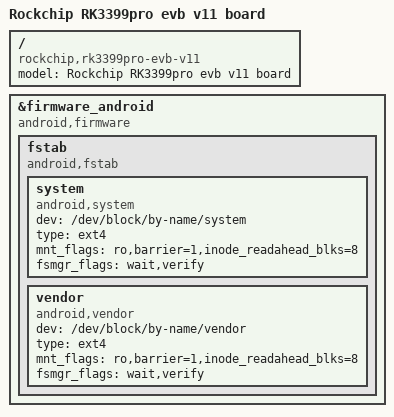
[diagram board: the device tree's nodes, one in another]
// SPDX-License-Identifier: (GPL-2.0+ OR MIT)
/*
 * Copyright (c) 2018 Fuzhou Rockchip Electronics Co., Ltd
 *
 */

/dts-v1/;
#include "rk3399pro-evb-v11.dtsi"

/ {
	model = "Rockchip RK3399pro evb v11 board";
	compatible = "rockchip,rk3399pro-evb-v11", "rockchip,rk3399pro";
};

&firmware_android {
	compatible = "android,firmware";
	fstab {
		compatible = "android,fstab";
		system {
			compatible = "android,system";
			dev = "/dev/block/by-name/system";
			type = "ext4";
			mnt_flags = "ro,barrier=1,inode_readahead_blks=8";
			fsmgr_flags = "wait,verify";
		};
		vendor {
			compatible = "android,vendor";
			dev = "/dev/block/by-name/vendor";
			type = "ext4";
			mnt_flags = "ro,barrier=1,inode_readahead_blks=8";
			fsmgr_flags = "wait,verify";
		};
	};
};
